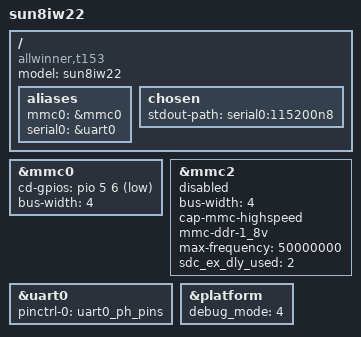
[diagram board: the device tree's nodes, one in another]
// SPDX-License-Identifier: (GPL-2.0+ or MIT)
/*
 * Allwinner Technology CO., Ltd. sun8iw21p1 platform
 *
 * modify base on juno.dts
 */

/dts-v1/;

#include "sun8iw22p1.dtsi"

/ {
	model = "sun8iw22";
	compatible = "allwinner,t153", "arm,sun8iw55p1";

	aliases {
		mmc0 = &mmc0;
		serial0 = &uart0;
	};

	chosen {
		stdout-path = "serial0:115200n8";
	};
};

&mmc0 {
	cd-gpios = <&pio 5 6 GPIO_ACTIVE_LOW>;	/* PF6 */
	bus-width = <4>;
	status = "okay";
};

&mmc2 {
	bus-width = <4>;
	cap-mmc-highspeed;
	mmc-ddr-1_8v;
	max-frequency = <50000000>;
	sdc_ex_dly_used = <2>;
    status = "disabled";
};

&uart0 {
	pinctrl-names = "default";
	pinctrl-0 = <&uart0_ph_pins>;
	status = "okay";
};

&platform {
	debug_mode = <4>;
};
